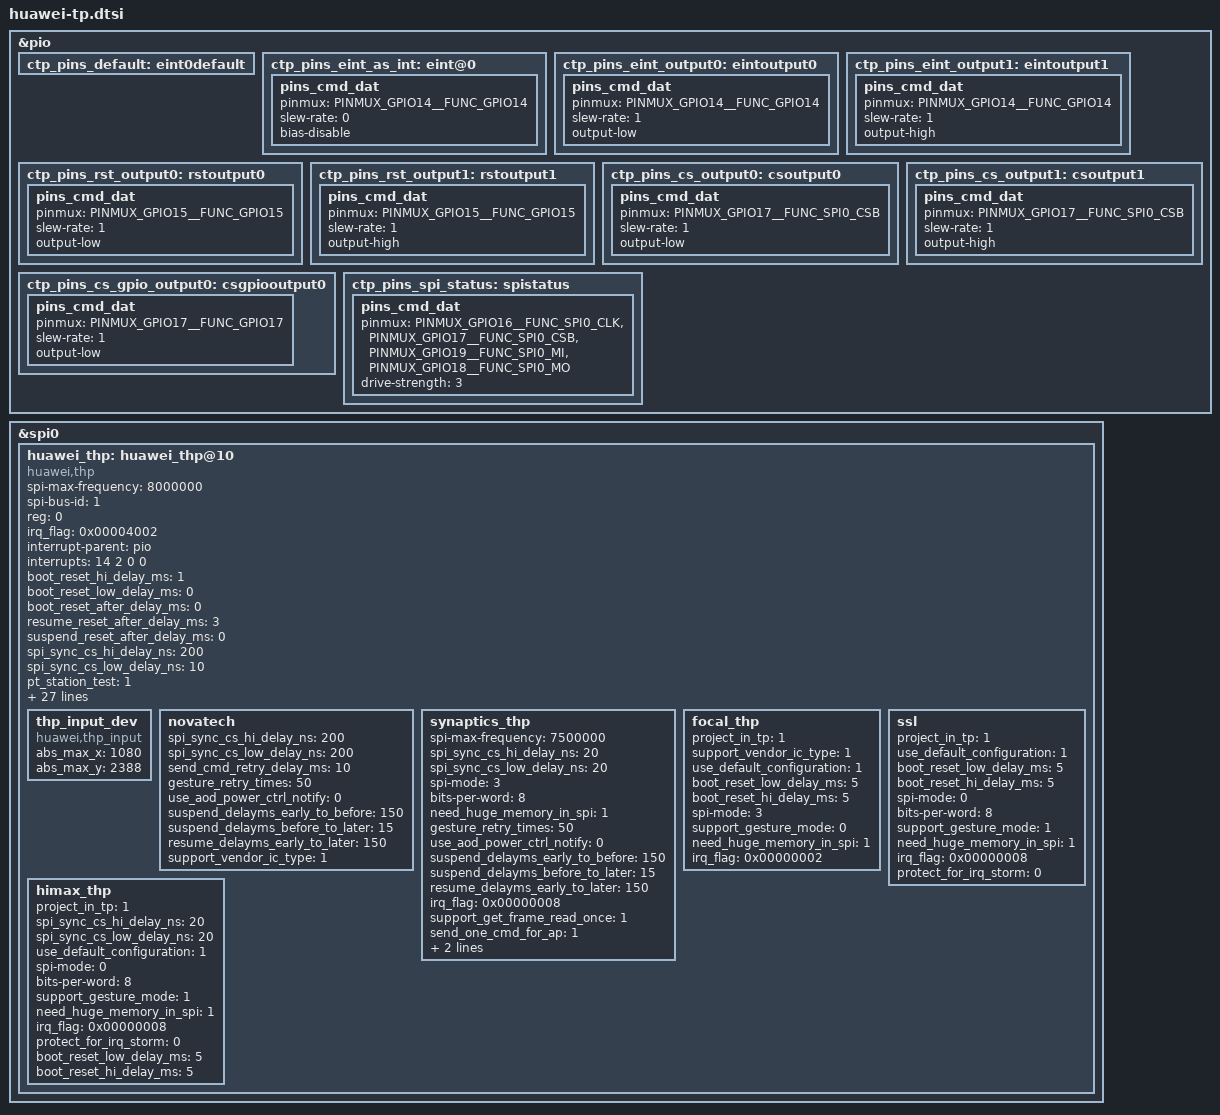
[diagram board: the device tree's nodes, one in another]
&pio {
	ctp_pins_default: eint0default {
	};
	ctp_pins_eint_as_int: eint@0 {
		pins_cmd_dat {
			pinmux = <PINMUX_GPIO14__FUNC_GPIO14>;
			slew-rate = <0>;
			bias-disable;
		};
	};
	ctp_pins_eint_output0: eintoutput0 {
		pins_cmd_dat {
			pinmux = <PINMUX_GPIO14__FUNC_GPIO14>;
			slew-rate = <1>;
			output-low;
		};
	};
	ctp_pins_eint_output1: eintoutput1 {
		pins_cmd_dat {
			pinmux = <PINMUX_GPIO14__FUNC_GPIO14>;
			slew-rate = <1>;
			output-high;
		};
	};
	ctp_pins_rst_output0: rstoutput0 {
		pins_cmd_dat {
			pinmux = <PINMUX_GPIO15__FUNC_GPIO15>;
			slew-rate = <1>;
			output-low;
		};
	};
	ctp_pins_rst_output1: rstoutput1 {
		pins_cmd_dat {
			pinmux = <PINMUX_GPIO15__FUNC_GPIO15>;
			slew-rate = <1>;
			output-high;
		};
	};

	ctp_pins_cs_output0: csoutput0 {
		pins_cmd_dat {
			pinmux = <PINMUX_GPIO17__FUNC_SPI0_CSB>;
			slew-rate = <1>;
			output-low;
		};
	};
	ctp_pins_cs_output1: csoutput1 {
		pins_cmd_dat {
			pinmux = <PINMUX_GPIO17__FUNC_SPI0_CSB>;
			slew-rate = <1>;
			output-high;
		};
	};
	ctp_pins_cs_gpio_output0: csgpiooutput0 {
		pins_cmd_dat {
			pinmux = <PINMUX_GPIO17__FUNC_GPIO17>;
			slew-rate = <1>;
			output-low;
		};
	};
	ctp_pins_spi_status: spistatus   {
		pins_cmd_dat {
			pinmux = <PINMUX_GPIO16__FUNC_SPI0_CLK>,
				 <PINMUX_GPIO17__FUNC_SPI0_CSB>,
				 <PINMUX_GPIO19__FUNC_SPI0_MI>,
				 <PINMUX_GPIO18__FUNC_SPI0_MO>;
			drive-strength = <3>;
		};
	};
};

&spi0 {
	status = "ok";
	huawei_thp: huawei_thp@10 {
		compatible = "huawei,thp";
		spi-max-frequency = <8000000>;
		spi-bus-id = <1>;
		reg = <0>;
		irq_flag = <0x00004002>;
		interrupt-parent = <&pio>;
		interrupts = <14 2 0 0>;
		boot_reset_hi_delay_ms = <1>;
		boot_reset_low_delay_ms = <0>;
		boot_reset_after_delay_ms = <0>;
		resume_reset_after_delay_ms = <3>;
		suspend_reset_after_delay_ms = <0>;
		spi_sync_cs_hi_delay_ns = <200>;
		spi_sync_cs_low_delay_ns = <10>;
		pt_station_test = <1>;
		proximity_support = <1>;
		support_pinctrl = <1>;
		hide_product_info_en = <1>;
		support_gesture_mode = <1>;
		lcd_gesture_mode_support = <1>;
		wait_afe_screen_on_support = <1>;
		early_suspend_delay_ms = <210>;
		need_enable_irq_wake = <1>;
		change_spi_driving_force = <1>;
		gesture_retry_times = <50>;
		use_ap_gesture = <0>;
		support_fingerprint_switch = <0>;
		aod_display_support = <0>;
		fast_booting_solution = <1>;
		supported_charger = <1>;
		need_notify_to_roi_algo = <1>;
		support_vendor_ic_type = <1>;

		pinctrl-names = "default", "idle", "state_eint_as_int", "state_rst_output0",
				"state_rst_output1", "state_cs_output0", "state_cs_output1", "state_spi_status";
		pinctrl-0 = <&ctp_pins_rst_output1 &ctp_pins_cs_output1>;
		pinctrl-1 = <&ctp_pins_rst_output0 &ctp_pins_cs_gpio_output0>;
		pinctrl-2 = <&ctp_pins_eint_as_int>;
		pinctrl-3 = <&ctp_pins_rst_output0>;
		pinctrl-4 = <&ctp_pins_rst_output1>;
		pinctrl-5 = <&ctp_pins_cs_output0>;
		pinctrl-6 = <&ctp_pins_cs_output1>;
		pinctrl-7 = <&ctp_pins_spi_status>;

		thp_input_dev {
			compatible = "huawei,thp_input";
			abs_max_x = <1080>;
			abs_max_y = <2388>;
		};
		novatech {
			spi_sync_cs_hi_delay_ns = <200>;
			spi_sync_cs_low_delay_ns = <200>;
			send_cmd_retry_delay_ms = <10>;
			gesture_retry_times = <50>;
			use_aod_power_ctrl_notify = <0>;
			suspend_delayms_early_to_before = <150>;
			suspend_delayms_before_to_later = <15>;
			resume_delayms_early_to_later = <150>;
			support_vendor_ic_type = <1>;
		};
		synaptics_thp {
			spi-max-frequency = <7500000>;
			spi_sync_cs_hi_delay_ns = <20>;
			spi_sync_cs_low_delay_ns = <20>;
			spi-mode = <3>;
			bits-per-word = <8>;
			need_huge_memory_in_spi = <1>;
			gesture_retry_times = <50>;
			use_aod_power_ctrl_notify = <0>;
			suspend_delayms_early_to_before = <150>;
			suspend_delayms_before_to_later = <15>;
			resume_delayms_early_to_later = <150>;
			/* IRQF_TRIGGER_LOW 0x00000008 */
			irq_flag = <0x00000008>;
			support_get_frame_read_once = <1>;
			send_one_cmd_for_ap = <1>;
			support_control_cs_off = <1>;
			support_vendor_ic_type = <0>;
		};
		focal_thp {
			project_in_tp = <1>;
			support_vendor_ic_type = <1>;
			use_default_configuration = <1>;
			boot_reset_low_delay_ms = <5>;
			boot_reset_hi_delay_ms = <5>;
			spi-mode = <3>;
			support_gesture_mode = <0>;
			need_huge_memory_in_spi = <1>;
			irq_flag = <0x00000002>;
		};
		ssl {
			project_in_tp = <1>;
			use_default_configuration = <1>;
			boot_reset_low_delay_ms = <5>;
			boot_reset_hi_delay_ms = <5>;
			spi-mode = <0>;
			bits-per-word = <8>;
			support_gesture_mode = <1>;
			need_huge_memory_in_spi = <1>;
			irq_flag = <0x00000008>;
			protect_for_irq_storm = <0>;
		};
		himax_thp {
			project_in_tp = <1>;
			spi_sync_cs_hi_delay_ns = <20>;
			spi_sync_cs_low_delay_ns = <20>;
			use_default_configuration = <1>;
			spi-mode = <0>;
			bits-per-word = <8>;
			support_gesture_mode = <1>;
			need_huge_memory_in_spi = <1>;
			irq_flag = <0x00000008>;
			protect_for_irq_storm = <0>;
			boot_reset_low_delay_ms = <5>;
			boot_reset_hi_delay_ms = <5>;
		};
	};
};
